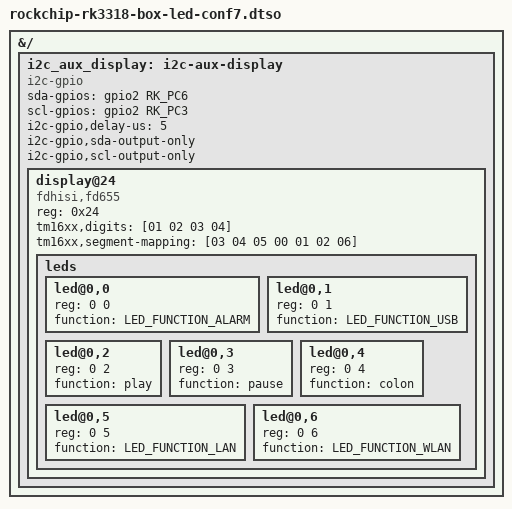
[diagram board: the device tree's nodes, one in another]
/dts-v1/;
/plugin/;

#include <dt-bindings/gpio/gpio.h>
#include <dt-bindings/leds/common.h>
#include <dt-bindings/pinctrl/rockchip.h>

/**
 * T9_RK3318 (T9 Sunwell 3318 version 4+32 GB)
 */

&{/} {

	i2c_aux_display: i2c-aux-display {

		compatible = "i2c-gpio";
		sda-gpios = <&gpio2 RK_PC6 (GPIO_ACTIVE_HIGH|GPIO_OPEN_DRAIN)>;
		scl-gpios = <&gpio2 RK_PC3 (GPIO_ACTIVE_HIGH|GPIO_OPEN_DRAIN)>;
		i2c-gpio,delay-us = <5>;
		i2c-gpio,sda-output-only;
		i2c-gpio,scl-output-only;
		#address-cells = <1>;
		#size-cells = <0>;

		display@24 {
			compatible = "fdhisi,fd655";
			reg = <0x24>;
			tm16xx,digits = [01 02 03 04];
			tm16xx,segment-mapping = [03 04 05 00 01 02 06];

			leds {
				#address-cells = <2>;
				#size-cells = <0>;

				led@0,0 {
					reg = <0 0>;
					function = LED_FUNCTION_ALARM;
				};

				led@0,1 {
					reg = <0 1>;
					function = LED_FUNCTION_USB;
				};

				led@0,2 {
					reg = <0 2>;
					function = "play";
				};

				led@0,3 {
					reg = <0 3>;
					function = "pause";
				};

				led@0,4 {
					reg = <0 4>;
					function = "colon";
				};

				led@0,5 {
					reg = <0 5>;
					function = LED_FUNCTION_LAN;
				};

				led@0,6 {
					reg = <0 6>;
					function = LED_FUNCTION_WLAN;
				};

			};

		};

	};

};
